# MIMXRT1051 register map
Vendor: nxp.com; File version: 1.0
CPU: CM7 r0p1, little endian, MPU, FPU, VTOR, 4 interrupt priority bits
Registers are 32-bit, read-write, reset 0x0 unless marked. A register's access mark holds for its fields unless they carry their own. Offsets are from the block's base; [hi:lo] are bit positions; {n}, {i} and the like mark numbered series; 'fields as' and 'values as' point back to an identical list.

## SEMC
Base 0x402F0000
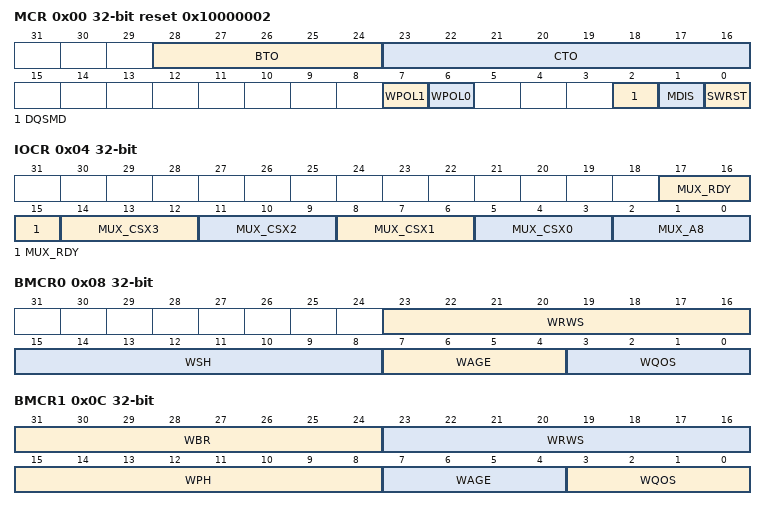
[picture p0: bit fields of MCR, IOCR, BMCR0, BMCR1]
0x00 MCR reset 0x10000002 — Module Control Register
  [28:24] BTO — Bus timeout cycles
    0=255*1; {v}=255*2 - 255*2^30 (v=1..9); 31=255*2^31
  [23:16] CTO — Command Execution timeout cycles
  [7] WPOL1 — WAIT/RDY# polarity for NAND
    0=Active low; 1=Active high
  [6] WPOL0 — WAIT/RDY# polarity for NOR/PSRAM
    0=Active low; 1=Active high
  [2] DQSMD — DQS (read strobe) mode
    0=Dummy read strobe loopbacked internally; 1=Dummy read strobe loopbacked from DQS pad
  [1] MDIS — Module Disable
    0=Module enabled; 1=Module disabled
  [0] SWRST — Software Reset
0x04 IOCR — IO Mux Control Register
  [17:15] MUX_RDY — SEMC_RDY function selection
    0=NAND Ready/Wait# input; 1=SDRAM CS1; 2=SDRAM CS2; 3=SDRAM CS3; 4=NOR CE#; 5=PSRAM CE#; 6=DBI CSX; 7=NOR/PSRAM Address bit 27
  [3n+5:3n+3] MUX_CSX{n} (n=0..3) — SEMC_CSX{n} output selection
    0=NOR/PSRAM Address bit {n+24} (A{n+24}); 1=SDRAM CS1; 2=SDRAM CS2; 3=SDRAM CS3; 4=NAND CE#; 5=NOR CE#; 6=PSRAM CE#; 7=DBI CSX
  [2:0] MUX_A8 — SEMC_A8 output selection
    0=SDRAM Address bit (A8); 1=NAND CE#; 2=NOR CE#; 3=PSRAM CE#; 4=DBI CSX; 5=SDRAM Address bit (A8); 6=SDRAM Address bit (A8); 7=SDRAM Address bit (A8)
0x08 BMCR0 — Bus (AXI) Master Control Register 0
  [23:16] WRWS — Weight of slave hit with Read/Write Switch. This weight score is valid when queue command's slave is same as current executing command with read/write operation switch.
  [15:8] WSH — Weight of Slave Hit without read/write switch. This weight score is valid when queue command's slave is same as current executing command without read/write operation switch.
  [7:4] WAGE — Weight of AGE calculation. Each command in queue has an age signal to indicate its wait period. It is multiplied by WAGE to get weight score.
  [3:0] WQOS — Weight of QOS calculation. AXI bus access has AxQOS signal set, which is used as a priority indicator for the associated write or read transaction. A higher value indicates a higher priority transaction. AxQOS is multiplied by WQOS to get weight score.
0x0C BMCR1 — Bus (AXI) Master Control Register 1
  [31:24] WBR — Weight of Bank Rotation. This weight score is valid when queue command's bank is not same as current executing command.
  [23:16] WRWS — Weight of slave hit without Read/Write Switch. This weight score is valid when queue command's read/write operation is same as current executing command.
  [15:8] WPH — Weight of Page Hit. This weight score is valid when queue command's page hits current executing command.
  [7:4] WAGE — Weight of AGE calculation. Each command in queue has an age signal to indicate its wait period. It is multiplied by WAGE to get weight score.
  [3:0] WQOS — Weight of QOS calculation. AXI bus access has AxQOS signal set, which is used as a priority indicator for the associated write or read transaction. A higher value indicates a higher priority transaction. AxQOS is multiplied by WQOS to get weight score.
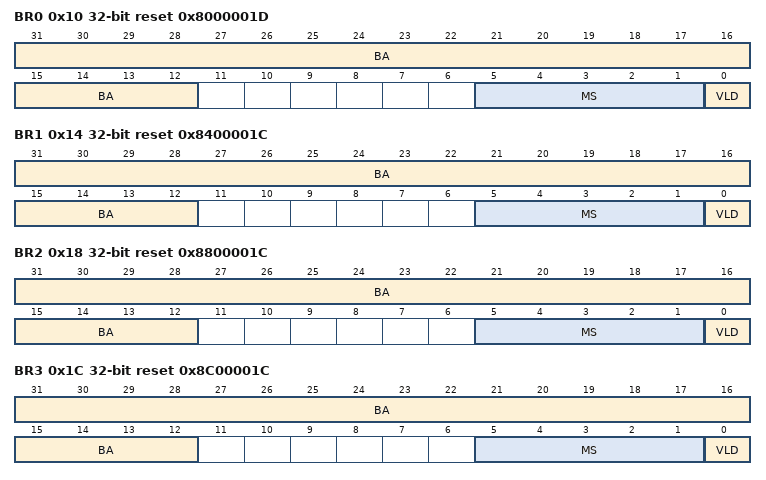
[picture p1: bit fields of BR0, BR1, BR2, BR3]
0x10 BR0 reset 0x8000001D — Base Register 0 (For SDRAM CS0 device)
  [31:12] BA — Base Address
  [5:1] MS — Memory size
    0=4KB; 1=8KB; 2=16KB; 3=32KB; 4=64KB; 5=128KB; 6=256KB; 7=512KB; 8=1MB; 9=2MB; 10=4MB; 11=8MB; 12=16MB; 13=32MB; 14=64MB; 15=128MB; 16=256MB; 17=512MB; 18=1GB; 19=2GB; {v}=4GB (v=20..31)
  [0] VLD — Valid
0x14 BR1 reset 0x8400001C — Base Register 1 (For SDRAM CS1 device)
  fields as BR0
0x18 BR2 reset 0x8800001C — Base Register 2 (For SDRAM CS2 device)
  fields as BR0
0x1C BR3 reset 0x8C00001C — Base Register 3 (For SDRAM CS3 device)
  fields as BR0
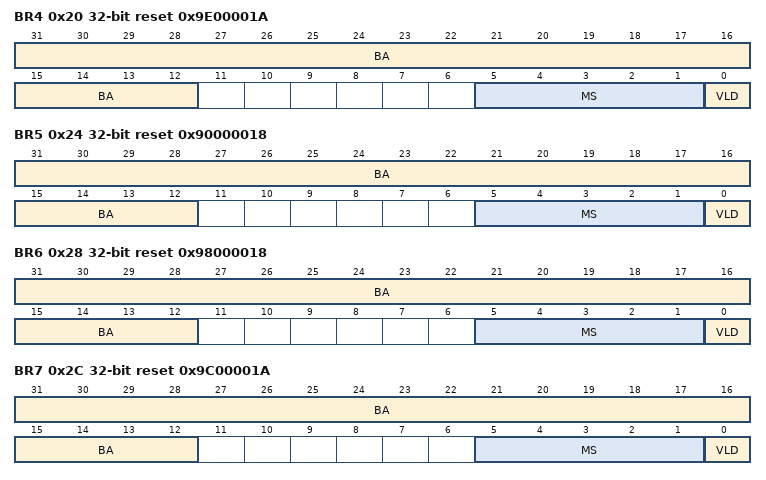
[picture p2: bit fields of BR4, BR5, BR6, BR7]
0x20 BR4 reset 0x9E00001A — Base Register 4 (For NAND device)
  fields as BR0
0x24 BR5 reset 0x90000018 — Base Register 5 (For NOR device)
  fields as BR0
0x28 BR6 reset 0x98000018 — Base Register 6 (For PSRAM device 0)
  fields as BR0
0x2C BR7 reset 0x9C00001A — Base Register 7 (For DBI-B (MIPI Display Bus Interface Type B) device)
  fields as BR0
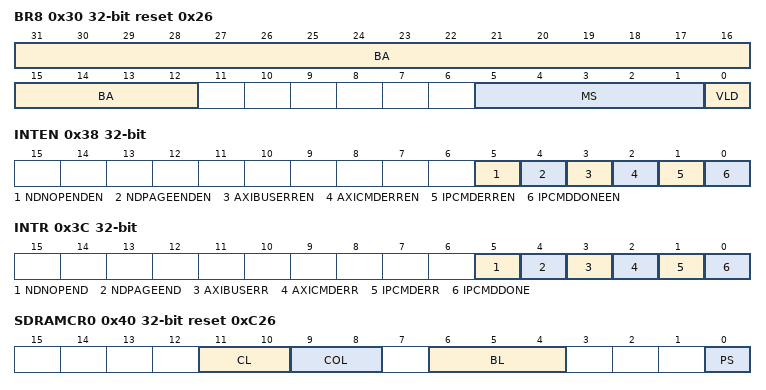
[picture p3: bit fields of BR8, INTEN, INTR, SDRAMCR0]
0x30 BR8 reset 0x26 — Base Register 8 (For NAND device)
  fields as BR0
0x38 INTEN — Interrupt Enable Register
  [all] fields
    0=Interrupt is disabled; 1=Interrupt is enabled
  [5] NDNOPENDEN — NAND no pending AXI access interrupt enable
  [4] NDPAGEENDEN — NAND page end interrupt enable
  [3] AXIBUSERREN — AXI bus error interrupt enable
  [2] AXICMDERREN — AXI command error interrupt enable
  [1] IPCMDERREN — IP command error interrupt enable
  [0] IPCMDDONEEN — IP command done interrupt enable
0x3C INTR — Interrupt Enable Register
  [5] NDNOPEND write-1-clears — NAND no pending AXI access interrupt
  [4] NDPAGEEND write-1-clears — NAND page end interrupt
  [3] AXIBUSERR write-1-clears — AXI bus error interrupt
  [2] AXICMDERR write-1-clears — AXI command error interrupt
  [1] IPCMDERR write-1-clears — IP command error done interrupt
  [0] IPCMDDONE write-1-clears — IP command normal done interrupt
0x40 SDRAMCR0 reset 0xC26 — SDRAM control register 0
  [11:10] CL — CAS Latency
    0=1; 1=1; 2=2; 3=3
  [9:8] COL — Column address bit number
    0=12 bit; 1=11 bit; 2=10 bit; 3=9 bit
  [6:4] BL — Burst Length
    0=1; 1=2; 2=4; {v}=8 (v=3..7)
  [0] PS — Port Size
    0=8bit; 1=16bit
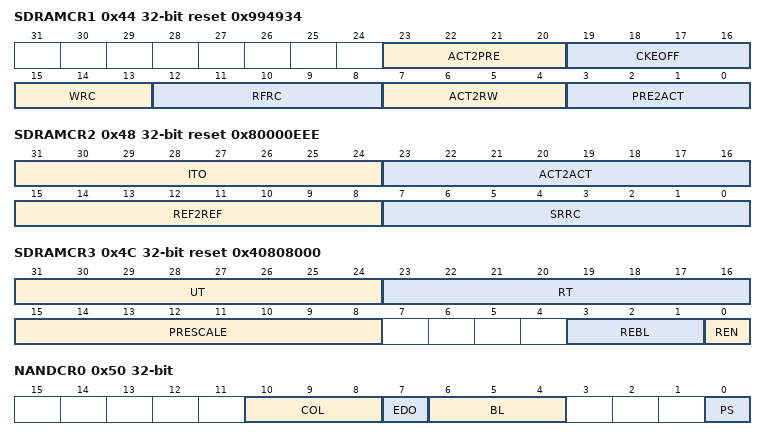
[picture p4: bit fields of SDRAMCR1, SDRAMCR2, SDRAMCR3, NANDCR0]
0x44 SDRAMCR1 reset 0x994934 — SDRAM control register 1
  [23:20] ACT2PRE — ACT to Precharge minimum time
  [19:16] CKEOFF — CKE OFF minimum time
  [15:13] WRC — Write recovery time
  [12:8] RFRC — Refresh recovery time
  [7:4] ACT2RW — ACT to Read/Write wait time
  [3:0] PRE2ACT — PRECHARGE to ACT/Refresh wait time
0x48 SDRAMCR2 reset 0x80000EEE — SDRAM control register 2
  [31:24] ITO — SDRAM Idle timeout
    0=IDLE timeout period is 256*Prescale period; {v}=IDLE timeout period is ITO*Prescale period (v=1..9)
  [23:16] ACT2ACT — ACT to ACT wait time
  [15:8] REF2REF — Refresh to Refresh wait time
  [7:0] SRRC — Self Refresh Recovery time
0x4C SDRAMCR3 reset 0x40808000 — SDRAM control register 3
  [31:24] UT — Refresh urgent threshold
    0=256*Prescaler period; {v}=UT*Prescaler period (v=1..9)
  [23:16] RT — Refresh timer period
    0=256*Prescaler period; {v}=RT*Prescaler period (v=1..9)
  [15:8] PRESCALE — Prescaler timer period
    0=256*16 clock cycles; {v}=PRESCALE*16 clock cycles (v=1..9)
  [3:1] REBL — Refresh burst length
    {v}={v+1} (v=0..7)
  [0] REN — Refresh enable
0x50 NANDCR0 — NAND control register 0
  [10:8] COL — Column address bit number
    0=16; 1=15; 2=14; 3=13; 4=12; 5=11; 6=10; 7=9
  [7] EDO — EDO mode enabled
    0=EDO mode disabled; 1=EDO mode enabled
  [6:4] BL — Burst Length
    0=1; 1=2; 2=4; 3=8; 4=16; 5=32; 6=64; 7=64
  [0] PS — Port Size
    0=8bit; 1=16bit
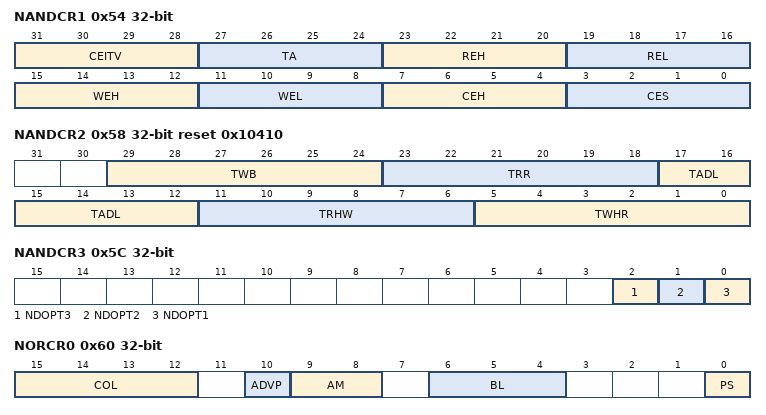
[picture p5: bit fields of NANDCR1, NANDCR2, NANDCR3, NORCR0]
0x54 NANDCR1 — NAND control register 1
  [31:28] CEITV — CE# interval time
  [27:24] TA — Turnaround time
  [23:20] REH — RE# high time
  [19:16] REL — RE# low time
  [15:12] WEH — WE# high time
  [11:8] WEL — WE# low time
  [7:4] CEH — CE hold time
  [3:0] CES — CE setup time
0x58 NANDCR2 reset 0x10410 — NAND control register 2
  [29:24] TWB — WE# high to busy wait time
  [23:18] TRR — Ready to RE# low wait time
  [17:12] TADL — ALE to write data start wait time
  [11:6] TRHW — RE# high to WE# low wait time
  [5:0] TWHR — WE# high to RE# low wait time
0x5C NANDCR3 — NAND control register 3
  [2] NDOPT3 — NAND option bit 3
  [1] NDOPT2 — NAND option bit 2
  [0] NDOPT1 — NAND option bit 1
0x60 NORCR0 — NOR control register 0
  [15:12] COL — Column Address bit width
    0=12 Bits; 1=11 Bits; 2=10 Bits; 3=9 Bits; 4=8 Bits; 5=7 Bits; 6=6 Bits; 7=5 Bits; 8=4 Bits; 9=3 Bits; 10=2 Bits; {v}=12 Bits (v=11..15)
  [10] ADVP — ADV# polarity
    0=ADV# is active low; 1=ADV# is active high
  [9:8] AM — Address Mode
    0=Address/Data MUX mode (ADMUX); 1=Advanced Address/Data MUX mode (AADM)
  [6:4] BL — Burst Length
    0=1; 1=2; 2=4; 3=8; 4=16; 5=32; 6=64; 7=64
  [0] PS — Port Size
    0=8bit; 1=16bit
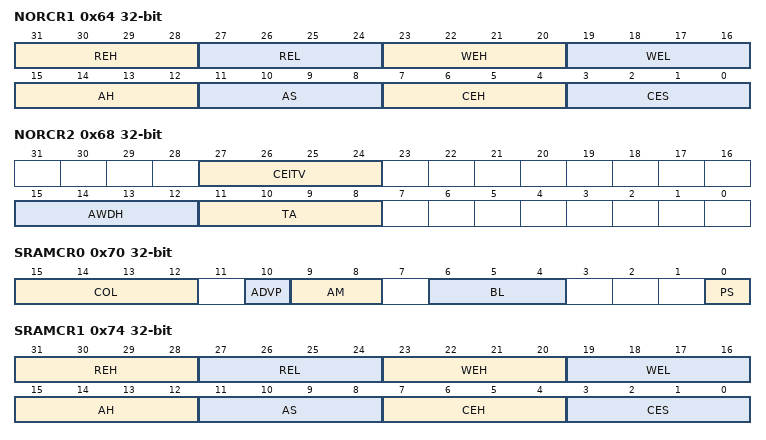
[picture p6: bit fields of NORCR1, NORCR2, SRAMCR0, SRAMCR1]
0x64 NORCR1 — NOR control register 1
  [31:28] REH — RE high time
  [27:24] REL — RE low time
  [23:20] WEH — WE high time
  [19:16] WEL — WE low time
  [15:12] AH — Address hold time
  [11:8] AS — Address setup time
  [7:4] CEH — CE hold time
  [3:0] CES — CE setup time
0x68 NORCR2 — NOR control register 2
  [27:24] CEITV — CE# interval time
  [15:12] AWDH — Address to write data hold time
  [11:8] TA — Turnaround time
0x6C NORCR3 — NOR control register 3
0x70 SRAMCR0 — SRAM control register 0
  fields as NORCR0
0x74 SRAMCR1 — SRAM control register 1
  fields as NORCR1
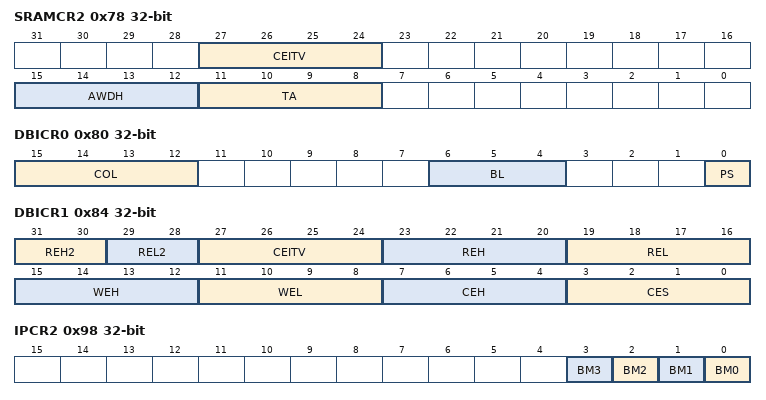
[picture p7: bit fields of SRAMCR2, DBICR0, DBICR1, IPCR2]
0x78 SRAMCR2 — SRAM control register 2
  fields as NORCR2
0x7C SRAMCR3 — SRAM control register 3
0x80 DBICR0 — DBI-B control register 0
  [15:12] COL — Column Address bit width
    values as NORCR0.COL
  [6:4] BL — Burst Length
    0=1; 1=2; 2=4; 3=8; 4=16; 5=32; 6=64; 7=64
  [0] PS — Port Size
    0=8bit; 1=16bit
0x84 DBICR1 — DBI-B control register 1
  [31:30] REH2 — RDX High Time bit [5:4]
  [29:28] REL2 — RDX Low Time bit [5:4]
  [27:24] CEITV — CSX interval time
  [23:20] REH — RDX High Time bit [3:0]
  [19:16] REL — RDX Low Time bit [3:0]
  [15:12] WEH — WRX High Time
  [11:8] WEL — WRX Low Time
  [7:4] CEH — CSX Hold Time
  [3:0] CES — CSX Setup Time
0x90 IPCR0 — IP Command control register 0
  [31:0] SA — Slave address
0x94 IPCR1 — IP Command control register 1
  [2:0] DATSZ — Data Size in Byte
    0=4; {v}={v} (v=1..4); 5=4; 6=4; 7=4
0x98 IPCR2 — IP Command control register 2
  [all] fields
    0=Byte Unmasked; 1=Byte Masked
  [n] BM{n} (n=0..3) — Byte Mask for Byte {n} (IPTXD bit {8n+7}:{8n})
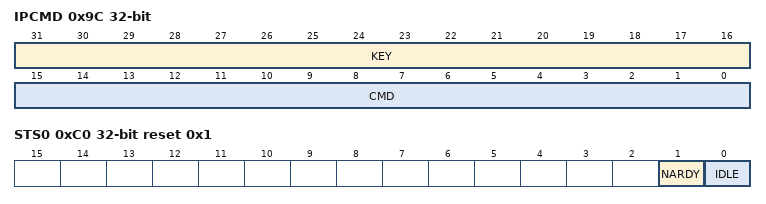
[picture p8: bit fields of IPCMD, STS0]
0x9C IPCMD — IP Command register
  [31:16] KEY wo — This field should be written with 0xA55A when trigging an IP command.
  [15:0] CMD — SDRAM Commands: 0x8: READ 0x9: WRITE 0xA: MODESET 0xB: ACTIVE 0xC: AUTO REFRESH 0xD: SELF REFRESH 0xE: PRECHARGE 0xF: PRECHARGE ALL Others: RSVD SELF REFRESH is sent to all SDRAM devices because they shared same SEMC_CLK pin
0xA0 IPTXDAT — TX DATA register (for IP Command)
  [31:0] DAT — data
0xB0 IPRXDAT ro — RX DATA register (for IP Command)
  [31:0] DAT — data
0xC0 STS0 ro reset 0x1 — Status register 0
  [1] NARDY — Indicating NAND device Ready/WAIT# pin level.
    0=NAND device is not ready; 1=NAND device is ready
  [0] IDLE — Indicating whether SEMC is in IDLE state.
0xC4 STS1 ro — Status register 1
0xC8 STS2 ro — Status register 2
  [3] NDWRPEND — This field indicating whether there is pending AXI command (write) to NAND device.
    0=No pending; 1=Pending
{0xC0+4i} STS{i} ro (i=3..11) — Status register {i}
0xF0 STS12 ro — Status register 12
  [31:0] NDADDR — This field indicating the last write address (AXI command) to NAND device (without base address in SEMC_BR4).
{0xC0+4i} STS{i} ro (i=13..15) — Status register {i}
